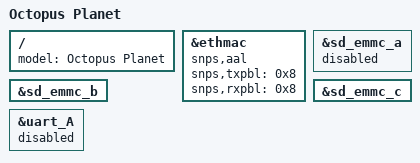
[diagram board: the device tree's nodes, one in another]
// SPDX-License-Identifier: (GPL-2.0+ OR MIT)
/*
 * Copyright (c) 2020 Flippy
 */

/dts-v1/;

#include "meson-gxm-q200.dts"

/ {
	model = "Octopus Planet";

};

&ethmac {
	snps,aal;
	snps,txpbl = <0x8>;
	snps,rxpbl = <0x8>;
};

&sd_emmc_a {
        status = "disabled";
};

&sd_emmc_b {
        status = "okay";
};

&sd_emmc_c {
        status = "okay";
};

&uart_A {
	status = "disabled";
};
